# f28p65x_mem_cfg_regs register map
Vendor: Texas Instruments
Peripheral module from a debugger description file (folder C2000).
Address unit: 16 bits
Registers are 32-bit, read-write, no defined reset value unless marked. A register's access mark holds for its fields unless they carry their own. Offsets are as the file gives them; lines under a group give offsets from that group; [hi:lo] are bit positions; {n}, {i} and the like mark numbered series; 'fields as' and 'values as' point back to an identical list; <NAME> marks a mode.

## MEM_CFG_REGS — MEM CFG Registers
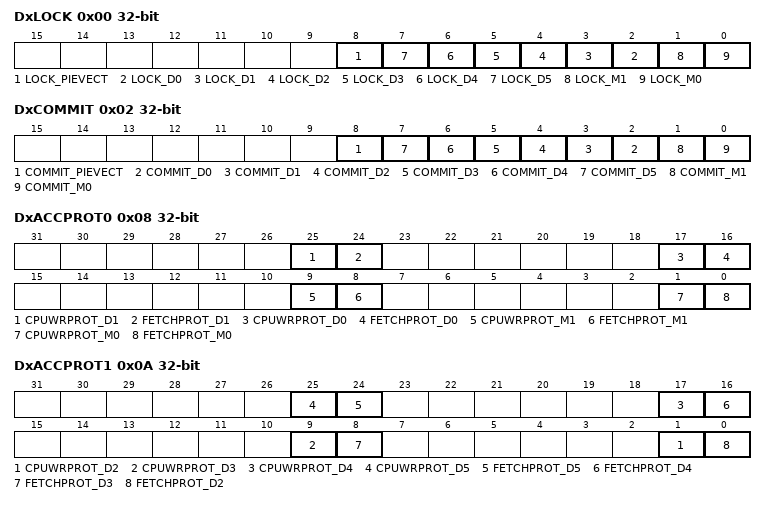
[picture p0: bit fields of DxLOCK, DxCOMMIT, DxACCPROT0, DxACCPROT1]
0x00 DxLOCK — Dedicated RAM Config Lock Register
  [8] LOCK_PIEVECT — PIEVECT RAM Lock bits
  [n+2] LOCK_D{n} (n=0..5) — D{n} RAM Lock bits
  [1] LOCK_M1 — M1 RAM Lock bits
  [0] LOCK_M0 — M0 RAM Lock bits
0x02 DxCOMMIT — Dedicated RAM Config Lock Commit Register
  [8] COMMIT_PIEVECT — PIEVECT RAM Permanent Lock bits
  [n+2] COMMIT_D{n} (n=0..5) — D{n} RAM Permanent Lock bits
  [1] COMMIT_M1 — M1 RAM Permanent Lock bits
  [0] COMMIT_M0 — M0 RAM Permanent Lock bits
0x08 DxACCPROT0 — Dedicated RAM Config Register
  [25] CPUWRPROT_D1 — CPU WR Protection For D1 RAM
  [24] FETCHPROT_D1 — Fetch Protection For D1 RAM
  [17] CPUWRPROT_D0 — CPU WR Protection For D0 RAM
  [16] FETCHPROT_D0 — Fetch Protection For D0 RAM
  [9] CPUWRPROT_M1 — CPU WR Protection For M1 RAM
  [8] FETCHPROT_M1 — Fetch Protection For M1 RAM
  [1] CPUWRPROT_M0 — CPU WR Protection For M0 RAM
  [0] FETCHPROT_M0 — Fetch Protection For M0 RAM
0x0A DxACCPROT1 — Dedicated RAM Config Register
  [8n-15] CPUWRPROT_D{n} (n=2..5) — CPU WR Protection For D{n} RAM
  [24] FETCHPROT_D5 — Fetch Protection For D5 RAM
  [16] FETCHPROT_D4 — Fetch Protection For D4 RAM
  [8] FETCHPROT_D3 — Fetch Protection For D3 RAM
  [0] FETCHPROT_D2 — Fetch Protection For D0 RAM
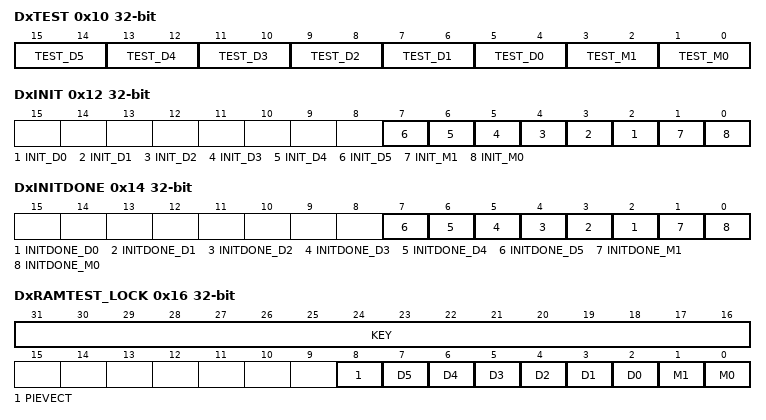
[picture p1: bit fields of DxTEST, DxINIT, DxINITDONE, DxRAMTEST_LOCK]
0x10 DxTEST — Dedicated RAM TEST Register
  [2n+5:2n+4] TEST_D{n} (n=0..5) — Selects the different modes for D{n} RAM
  [3:2] TEST_M1 — Selects the different modes for M1 RAM
  [1:0] TEST_M0 — Selects the different modes for M0 RAM
0x12 DxINIT — Dedicated RAM Init Register
  [n+2] INIT_D{n} (n=0..5) — RAM Initialization control for D{n} RAM.
  [1] INIT_M1 — RAM Initialization control for M1 RAM.
  [0] INIT_M0 — RAM Initialization control for M0 RAM.
0x14 DxINITDONE ro — Dedicated RAM InitDone Status Register
  [n+2] INITDONE_D{n} (n=0..5) — RAM Initialization status for D{n} RAM.
  [1] INITDONE_M1 — RAM Initialization status for M1 RAM.
  [0] INITDONE_M0 — RAM Initialization status for M0 RAM.
0x16 DxRAMTEST_LOCK — Lock register to Dx RAM TEST registers
  [31:16] KEY — Key for writing DxRAMTEST_LOCK
  [8] PIEVECT — DxTEST.TEST_PIEVECT LOCK
  [n+2] D{n} (n=0..5) — DxTEST.TEST_D{n} LOCK
  [1] M1 — DxTEST.TEST_M1 LOCK
  [0] M0 — DxTEST.TEST_M0 LOCK
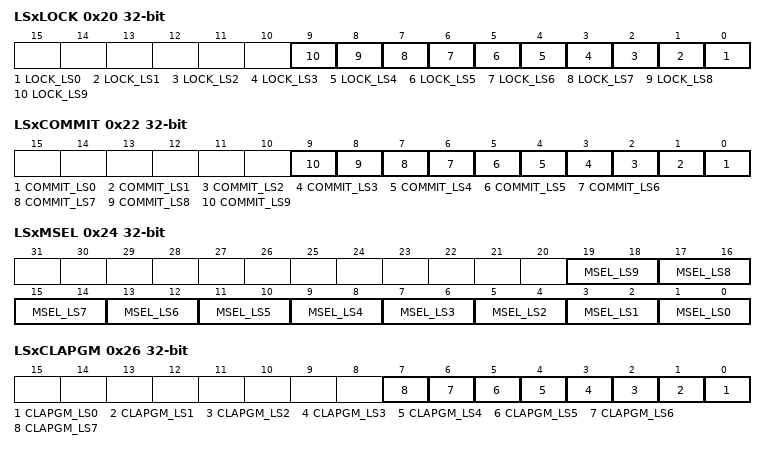
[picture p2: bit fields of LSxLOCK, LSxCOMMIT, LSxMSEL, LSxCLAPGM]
0x20 LSxLOCK — Local Shared RAM Config Lock Register
  [n] LOCK_LS{n} (n=0..9) — LS{n} RAM Lock bits
0x22 LSxCOMMIT — Local Shared RAM Config Lock Commit Register
  [n] COMMIT_LS{n} (n=0..9) — LS{n} RAM Permanent Lock bits
0x24 LSxMSEL — Local Shared RAM Controller Sel Register
  [2n+1:2n] MSEL_LS{n} (n=0..9) — Controller Select for LS{n} RAM
0x26 LSxCLAPGM — Local Shared RAM Prog/Exe control Register
  [n] CLAPGM_LS{n} (n=0..7) — Selects LS{n} RAM as program vs data memory for CLA
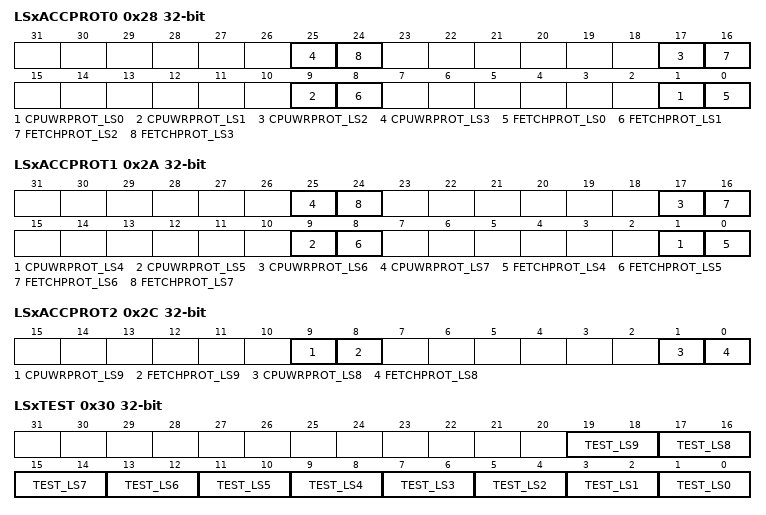
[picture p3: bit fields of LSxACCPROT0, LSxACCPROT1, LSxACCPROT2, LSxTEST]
0x28 LSxACCPROT0 — Local Shared RAM Config Register 0
  [8n+1] CPUWRPROT_LS{n} (n=0..3) — CPU WR Protection For LS{n} RAM
  [8n] FETCHPROT_LS{n} (n=0..3) — Fetch Protection For LS{n} RAM
0x2A LSxACCPROT1 — Local Shared RAM Config Register 1
  [8n-31] CPUWRPROT_LS{n} (n=4..7) — CPU WR Protection For LS{n} RAM
  [8n-32] FETCHPROT_LS{n} (n=4..7) — Fetch Protection For LS{n} RAM
0x2C LSxACCPROT2 — Local Shared RAM Config Register 2
  [9] CPUWRPROT_LS9 — CPU WR Protection For LS9 RAM
  [8] FETCHPROT_LS9 — Fetch Protection For LS9 RAM
  [1] CPUWRPROT_LS8 — CPU WR Protection For LS8 RAM
  [0] FETCHPROT_LS8 — Fetch Protection For LS8 RAM
0x30 LSxTEST — Local Shared RAM TEST Register
  [2n+1:2n] TEST_LS{n} (n=0..9) — Selects the different modes for LS{n} RAM
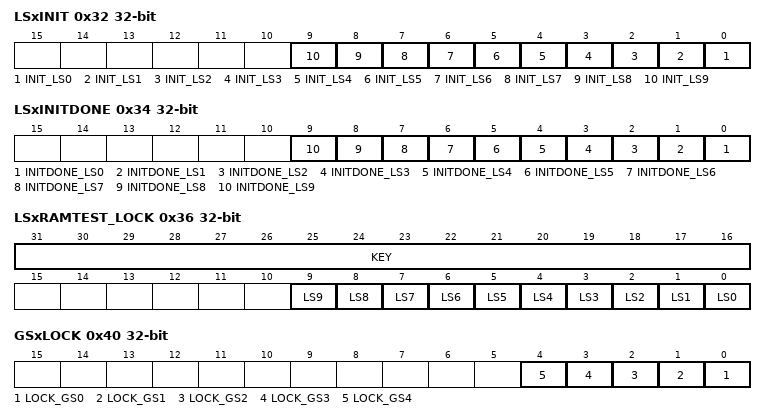
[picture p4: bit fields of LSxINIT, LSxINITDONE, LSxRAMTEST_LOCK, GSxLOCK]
0x32 LSxINIT — Local Shared RAM Init Register
  [n] INIT_LS{n} (n=0..9) — RAM Initialization control for LS{n} RAM.
0x34 LSxINITDONE ro — Local Shared RAM InitDone Status Register
  [n] INITDONE_LS{n} (n=0..9) — RAM Initialization status for LS{n} RAM.
0x36 LSxRAMTEST_LOCK — Lock register to LSx RAM TEST registers
  [31:16] KEY — KEY to enable write to lock
  [n] LS{n} (n=0..9) — LSxTEST.TEST_LS{n} LOCK
0x40 GSxLOCK — Global Shared RAM Config Lock Register
  [n] LOCK_GS{n} (n=0..4) — GS{n} RAM Lock bits
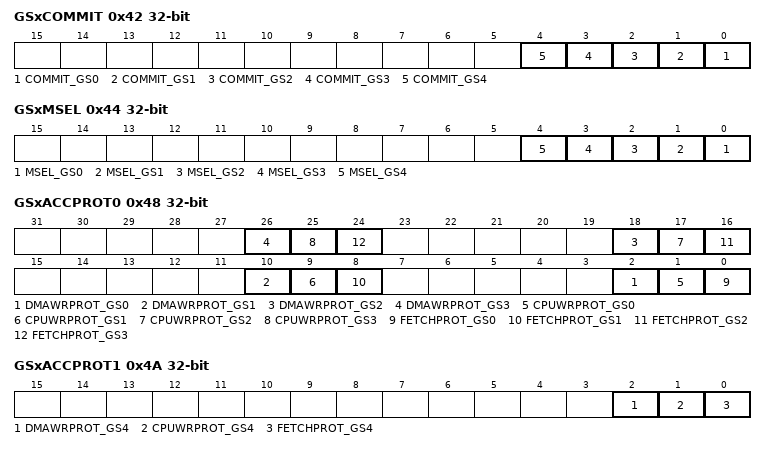
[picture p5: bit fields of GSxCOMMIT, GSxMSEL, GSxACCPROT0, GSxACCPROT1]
0x42 GSxCOMMIT — Global Shared RAM Config Lock Commit Register
  [n] COMMIT_GS{n} (n=0..4) — GS{n} RAM Permanent Lock bits
0x44 GSxMSEL — Global Shared RAM Controller Sel Register
  [n] MSEL_GS{n} (n=0..4) — Controller Select for GS{n} RAM
0x48 GSxACCPROT0 — Global Shared RAM Config Register 0
  [8n+2] DMAWRPROT_GS{n} (n=0..3) — DMA WR Protection For GS{n} RAM
  [8n+1] CPUWRPROT_GS{n} (n=0..3) — CPU WR Protection For GS{n} RAM
  [8n] FETCHPROT_GS{n} (n=0..3) — Fetch Protection For GS{n} RAM
0x4A GSxACCPROT1 — Global Shared RAM Config Register 1
  [2] DMAWRPROT_GS4 — DMA WR Protection For GS4 RAM
  [1] CPUWRPROT_GS4 — CPU WR Protection For GS4 RAM
  [0] FETCHPROT_GS4 — Fetch Protection For GS4 RAM
0x4C GSxACCPROT2 access not given — Global Shared RAM Config Register 2
0x4E GSxACCPROT3 access not given — Global Shared RAM Config Register 3
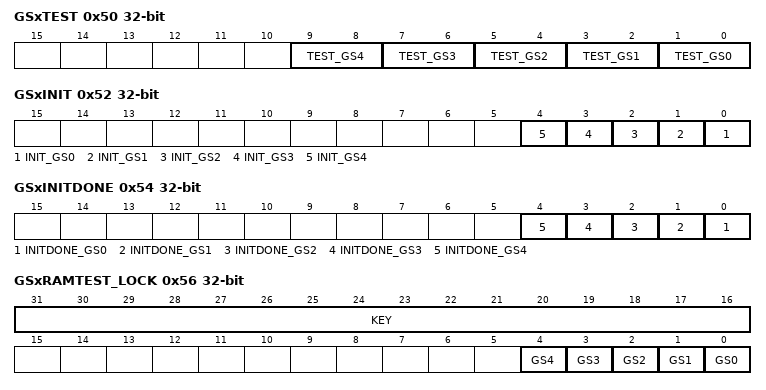
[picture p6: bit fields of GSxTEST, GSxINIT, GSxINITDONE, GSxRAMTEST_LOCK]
0x50 GSxTEST — Global Shared RAM TEST Register
  [2n+1:2n] TEST_GS{n} (n=0..4) — Selects the different modes for GS{n} RAM
0x52 GSxINIT — Global Shared RAM Init Register
  [n] INIT_GS{n} (n=0..4) — RAM Initialization control for GS{n} RAM.
0x54 GSxINITDONE ro — Global Shared RAM InitDone Status Register
  [n] INITDONE_GS{n} (n=0..4) — RAM Initialization status for GS{n} RAM.
0x56 GSxRAMTEST_LOCK — Lock register to GSx RAM TEST registers
  [31:16] KEY — KEY to enable write to lock
  [n] GS{n} (n=0..4) — GSxTEST.TEST_GS{n} LOCK
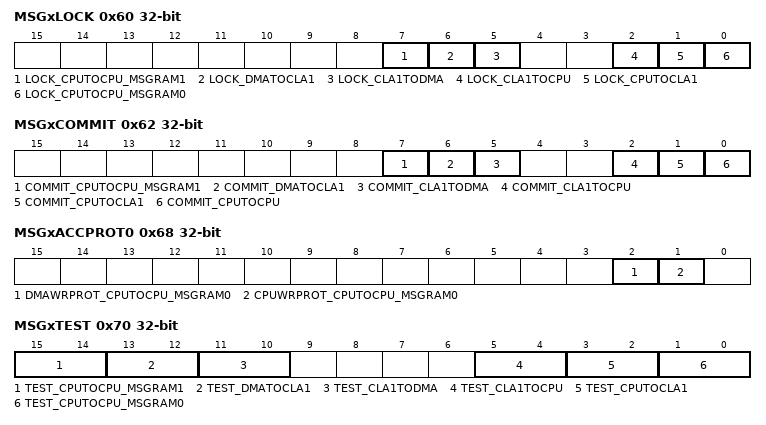
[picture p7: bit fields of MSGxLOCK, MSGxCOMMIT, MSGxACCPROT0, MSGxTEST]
0x60 MSGxLOCK — Message RAM Config Lock Register
  [7] LOCK_CPUTOCPU_MSGRAM1 — Lock bit of CPU to CPU MSG RAM1 control fields
  [6] LOCK_DMATOCLA1 — DMATOCLA1 RAM control fields lock bit
  [5] LOCK_CLA1TODMA — CLA1TODMA RAM control fields lock bit
  [2] LOCK_CLA1TOCPU — CLA1TOCPU RAM Lock bits
  [1] LOCK_CPUTOCLA1 — CPUTOCLA1 RAM Lock bits
  [0] LOCK_CPUTOCPU_MSGRAM0 — CPUTOCPU RAM Lock bits
0x62 MSGxCOMMIT — Message RAM Config Lock Commit Register
  [7] COMMIT_CPUTOCPU_MSGRAM1 — Commint bit of CPU to CPU MSG RAM1 control fields
  [6] COMMIT_DMATOCLA1 — DMATOCLA1 RAM control fields COMMIT bit
  [5] COMMIT_CLA1TODMA — CLA1TODMA RAM control fields COMMIT bit
  [2] COMMIT_CLA1TOCPU — CLA1TOCPU RAM control fields COMMIT bit
  [1] COMMIT_CPUTOCLA1 — CPUTOCLA1 RAM control fields COMMIT bit
  [0] COMMIT_CPUTOCPU — CPUTOCPU RAM control fields COMMIT bit
0x68 MSGxACCPROT0 — Message RAM Access Protection Register 0
  [2] DMAWRPROT_CPUTOCPU_MSGRAM0 — DMA WR Protection For CPUTOCPU_MSGRAM0 RAM
  [1] CPUWRPROT_CPUTOCPU_MSGRAM0 — CPU WR Protection For CPUTOCPU_MSGRAM0 RAM
0x70 MSGxTEST — Message RAM TEST Register
  [15:14] TEST_CPUTOCPU_MSGRAM1 — CPU to CPU Mode Select
  [13:12] TEST_DMATOCLA1 — DMA to CLA1 MSG RAM Mode Select
  [11:10] TEST_CLA1TODMA — CLA1 to DMA MSG RAM Mode Select
  [5:4] TEST_CLA1TOCPU — CLA1 to CPU MSG RAM Mode Select
  [3:2] TEST_CPUTOCLA1 — CPU to CLA1 MSG RAM Mode Select
  [1:0] TEST_CPUTOCPU_MSGRAM0 — CPU to CPU Mode Select
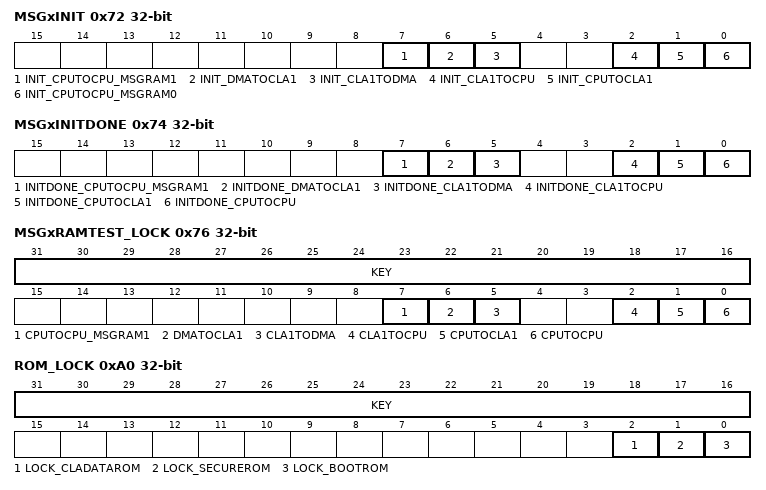
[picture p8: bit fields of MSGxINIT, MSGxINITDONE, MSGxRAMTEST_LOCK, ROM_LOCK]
0x72 MSGxINIT — Message RAM Init Register
  [7] INIT_CPUTOCPU_MSGRAM1 — Initialization control for CPU to CPU MSG RAM1
  [6] INIT_DMATOCLA1 — Initialization control for DMA to CLA1 MSG RAM
  [5] INIT_CLA1TODMA — Initialization control for CLA1 to DMA MSG RAM
  [2] INIT_CLA1TOCPU — Initialization control for CLA1TOCPU MSG RAM
  [1] INIT_CPUTOCLA1 — Initialization control for CPUTOCLA1 MSG RAM
  [0] INIT_CPUTOCPU_MSGRAM0 — Initialization control for CPU to CPU MSG RAM
0x74 MSGxINITDONE ro — Message RAM InitDone Status Register
  [7] INITDONE_CPUTOCPU_MSGRAM1 — Initialization status for CPU to CPU MSG RAM1
  [6] INITDONE_DMATOCLA1 — Initialization status for DMA to CLA1 MSG RAM
  [5] INITDONE_CLA1TODMA — Initialization status for CLA1 to DMA MSG RAM
  [2] INITDONE_CLA1TOCPU — Initialization status for CLA1 to CPU MSG RAM
  [1] INITDONE_CPUTOCLA1 — Initialization status for CPU to CLA1 MSG RAM
  [0] INITDONE_CPUTOCPU — Initialization status for CPU to CPU MSG RAM
0x76 MSGxRAMTEST_LOCK — Lock register for MSGx RAM TEST Register
  [31:16] KEY — KEY to enable write to lock
  [7] CPUTOCPU_MSGRAM1 — MSGxRAMTEST_LOCK.CPUTOCPU_MSGRAM1Lock Configuration
  [6] DMATOCLA1 — MSGxRAMTEST_LOCK.DMATOCLA1Lock Configuration
  [5] CLA1TODMA — MSGxRAMTEST_LOCK.CLA1TODMALock Configuration
  [2] CLA1TOCPU — MSGxRAMTEST_LOCK.CLA1TOCPULock Configuration
  [1] CPUTOCLA1 — MSGxRAMTEST_LOCK.CPUTOCLA1Lock Configuration
  [0] CPUTOCPU — MSGxRAMTEST_LOCK.CPUTOCPULock Configuration
0xA0 ROM_LOCK — ROM Config Lock Register
  [31:16] KEY — Key for writing ROM LOCK
  [2] LOCK_CLADATAROM — CLADATAROM Lock bits
  [1] LOCK_SECUREROM — SECUREROM Lock bits
  [0] LOCK_BOOTROM — BOOTROM Lock bits
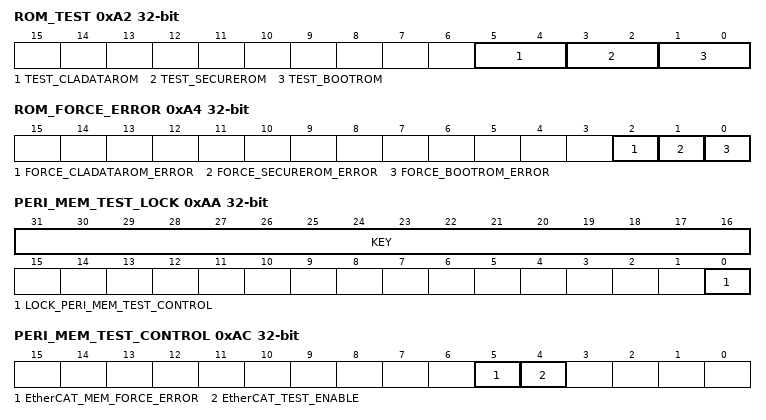
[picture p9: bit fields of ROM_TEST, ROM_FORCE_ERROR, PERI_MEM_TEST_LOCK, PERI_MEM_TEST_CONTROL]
0xA2 ROM_TEST
  [5:4] TEST_CLADATAROM — Selects the different modes for CLADATAROM
  [3:2] TEST_SECUREROM — Selects the different modes for SECUREROM
  [1:0] TEST_BOOTROM — Selects the different modes for BOOTROM
0xA4 ROM_FORCE_ERROR
  [2] FORCE_CLADATAROM_ERROR — Force CLADATAROM Parity Error
  [1] FORCE_SECUREROM_ERROR — Force SECUREROM Parity Error
  [0] FORCE_BOOTROM_ERROR — Force Bootrom Parity Error
0xAA PERI_MEM_TEST_LOCK — Peripheral Memory Test Lock Register
  [31:16] KEY — KEY to lock Peripheral memory test
  [0] LOCK_PERI_MEM_TEST_CONTROL — PERI_MEM_TEST_CONTROL Lock bit
0xAC PERI_MEM_TEST_CONTROL — Peripheral Memory Test control Register
  [5] EtherCAT_MEM_FORCE_ERROR — Force Parity Error on EtherCAT RAM
  [4] EtherCAT_TEST_ENABLE — EtherCAT Test mode enable
